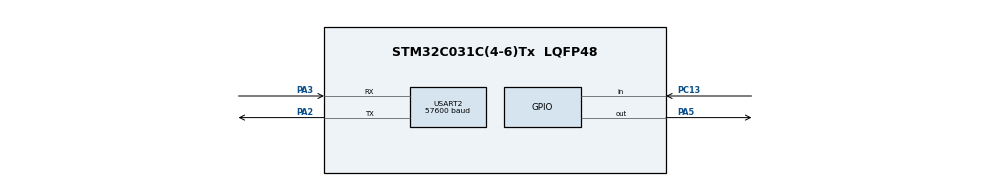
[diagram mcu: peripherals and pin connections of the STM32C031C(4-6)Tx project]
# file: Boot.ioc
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Mcu.Family=STM32C0
Mcu.Name=STM32C031C(4-6)Tx
Mcu.Package=LQFP48
PA2.Mode=Asynchronous
PA2.Signal=USART2_TX
PA3.Mode=Asynchronous
PA3.Signal=USART2_RX
PA5.Signal=GPIO_Output
PC13.Signal=GPIO_Input
PF0-OSC_IN\ (PF0).Mode=HSE-External-Oscillator
PF0-OSC_IN\ (PF0).Signal=RCC_OSC_IN
PF1-OSC_OUT\ (PF1).Mode=HSE-External-Oscillator
PF1-OSC_OUT\ (PF1).Signal=RCC_OSC_OUT
ProjectManager.HeapSize=0x200
ProjectManager.StackSize=0x400
ProjectManager.TargetToolchain=STM32CubeIDE
RCC.ADCFreq_Value=48000000
RCC.AHBFreq_Value=48000000
RCC.CortexFreq_Value=48000000
RCC.EXTERNAL_CLOCK_VALUE=12288000
RCC.HCLKFreq_Value=48000000
RCC.HSE_VALUE=48000000
RCC.HSISYSCLKDivider=RCC_HSI_DIV1
RCC.HSI_VALUE=48000000
RCC.LSE_VALUE=32768
RCC.SYSCLKFreq_VALUE=48000000
RCC.SYSCLKSource=RCC_SYSCLKSOURCE_HSE
USART2.BaudRate=57600
USART2.VirtualMode-Asynchronous=VM_ASYNC
board=NUCLEO-C031C6

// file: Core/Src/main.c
/* USER CODE BEGIN Header */
/**
  ******************************************************************************
  * @file           : main.c
  * @brief          : Main program body
  ******************************************************************************
  * @attention
  *
  * Copyright (c) 2023 STMicroelectronics.
  * All rights reserved.
  *
  * This software is licensed under terms that can be found in the LICENSE file
  * in the root directory of this software component.
  * If no LICENSE file comes with this software, it is provided AS-IS.
  *
  ******************************************************************************
  */
/* USER CODE END Header */
#include "main.h"

/* USER CODE BEGIN Includes */
#include "app.h"
/* USER CODE END Includes */

void SystemClock_Config(void);
static void MX_GPIO_Init(void);
static void MX_USART2_UART_Init(void);

int main(void)
{

  /* MCU Configuration--------------------------------------------------------*/

  /* Reset of all peripherals, Initializes the Flash interface and the Systick. */
  HAL_Init();

  /* USER CODE BEGIN Init */
  /* De-initialize the RCC to make sure the RCC_CR_HSEBYP-bit is cleared. Otherwise
   * the HSE cannot be configured, resulting in LL_RCC_HSE_IsReady() failing.
   */
  LL_RCC_DeInit();
  /* USER CODE END Init */

  /* Configure the system clock */
  SystemClock_Config();

  /* Initialize all configured peripherals */
  MX_GPIO_Init();
  MX_USART2_UART_Init();
  /* USER CODE BEGIN 2 */
  /* Initialize the bootloader application. */
  AppInit();
  /* USER CODE END 2 */

  /* Infinite loop */
  /* USER CODE BEGIN WHILE */
  while (1)
  {
    /* Run the bootloader application. */
    AppTask();
    /* USER CODE END WHILE */

  }
}

void SystemClock_Config(void)
{
  LL_FLASH_SetLatency(LL_FLASH_LATENCY_1);

  /* HSE configuration and activation */
  LL_RCC_HSE_Enable();
  while(LL_RCC_HSE_IsReady() != 1)
  {
  }

  /* Set AHB prescaler*/
  LL_RCC_SetAHBPrescaler(LL_RCC_SYSCLK_DIV_1);

  /* Sysclk activation on the HSE */
  LL_RCC_SetSysClkSource(LL_RCC_SYS_CLKSOURCE_HSE);
  while(LL_RCC_GetSysClkSource() != LL_RCC_SYS_CLKSOURCE_STATUS_HSE)
  {
  }

  /* Set APB1 prescaler*/
  LL_RCC_SetAPB1Prescaler(LL_RCC_APB1_DIV_1);
  /* Update CMSIS variable (which can be updated also through SystemCoreClockUpdate function) */
  LL_SetSystemCoreClock(48000000);

   /* Update the time base */
  if (HAL_InitTick (TICK_INT_PRIORITY) != HAL_OK)
  {
    Error_Handler();
  }
}

static void MX_USART2_UART_Init(void)
{

  LL_USART_InitTypeDef USART_InitStruct = {0};

  LL_GPIO_InitTypeDef GPIO_InitStruct = {0};

  /* Peripheral clock enable */
  LL_APB1_GRP1_EnableClock(LL_APB1_GRP1_PERIPH_USART2);

  LL_IOP_GRP1_EnableClock(LL_IOP_GRP1_PERIPH_GPIOA);
  /**USART2 GPIO Configuration
  PA2   ------> USART2_TX
  PA3   ------> USART2_RX
  */
  GPIO_InitStruct.Pin = LL_GPIO_PIN_2;
  GPIO_InitStruct.Mode = LL_GPIO_MODE_ALTERNATE;
  GPIO_InitStruct.Speed = LL_GPIO_SPEED_FREQ_LOW;
  GPIO_InitStruct.OutputType = LL_GPIO_OUTPUT_PUSHPULL;
  GPIO_InitStruct.Pull = LL_GPIO_PULL_NO;
  GPIO_InitStruct.Alternate = LL_GPIO_AF_1;
  LL_GPIO_Init(GPIOA, &GPIO_InitStruct);

  GPIO_InitStruct.Pin = LL_GPIO_PIN_3;
  GPIO_InitStruct.Mode = LL_GPIO_MODE_ALTERNATE;
  GPIO_InitStruct.Speed = LL_GPIO_SPEED_FREQ_LOW;
  GPIO_InitStruct.OutputType = LL_GPIO_OUTPUT_PUSHPULL;
  GPIO_InitStruct.Pull = LL_GPIO_PULL_NO;
  GPIO_InitStruct.Alternate = LL_GPIO_AF_1;
  LL_GPIO_Init(GPIOA, &GPIO_InitStruct);

  /* USER CODE BEGIN USART2_Init 1 */
  /* Note that the USART initialization that follows here is don't care. It is
   * reconfigured upon bootloader initialization with function Rs232Init().
   */
  /* USER CODE END USART2_Init 1 */
  USART_InitStruct.PrescalerValue = LL_USART_PRESCALER_DIV1;
  USART_InitStruct.BaudRate = 57600;
  USART_InitStruct.DataWidth = LL_USART_DATAWIDTH_8B;
  USART_InitStruct.StopBits = LL_USART_STOPBITS_1;
  USART_InitStruct.Parity = LL_USART_PARITY_NONE;
  USART_InitStruct.TransferDirection = LL_USART_DIRECTION_TX_RX;
  USART_InitStruct.HardwareFlowControl = LL_USART_HWCONTROL_NONE;
  USART_InitStruct.OverSampling = LL_USART_OVERSAMPLING_16;
  LL_USART_Init(USART2, &USART_InitStruct);
  LL_USART_ConfigAsyncMode(USART2);

  LL_USART_Enable(USART2);

  /* Polling USART2 initialisation */
  while((!(LL_USART_IsActiveFlag_TEACK(USART2))) || (!(LL_USART_IsActiveFlag_REACK(USART2))))
  {
  }

}

static void MX_GPIO_Init(void)
{
  LL_GPIO_InitTypeDef GPIO_InitStruct = {0};

  /* GPIO Ports Clock Enable */
  LL_IOP_GRP1_EnableClock(LL_IOP_GRP1_PERIPH_GPIOC);
  LL_IOP_GRP1_EnableClock(LL_IOP_GRP1_PERIPH_GPIOF);
  LL_IOP_GRP1_EnableClock(LL_IOP_GRP1_PERIPH_GPIOA);

  /**/
  LL_GPIO_ResetOutputPin(GPIOA, LL_GPIO_PIN_5);

  /**/
  GPIO_InitStruct.Pin = LL_GPIO_PIN_13;
  GPIO_InitStruct.Mode = LL_GPIO_MODE_INPUT;
  GPIO_InitStruct.Pull = LL_GPIO_PULL_NO;
  LL_GPIO_Init(GPIOC, &GPIO_InitStruct);

  /**/
  GPIO_InitStruct.Pin = LL_GPIO_PIN_5;
  GPIO_InitStruct.Mode = LL_GPIO_MODE_OUTPUT;
  GPIO_InitStruct.Speed = LL_GPIO_SPEED_FREQ_LOW;
  GPIO_InitStruct.OutputType = LL_GPIO_OUTPUT_PUSHPULL;
  GPIO_InitStruct.Pull = LL_GPIO_PULL_NO;
  LL_GPIO_Init(GPIOA, &GPIO_InitStruct);

}

void Error_Handler(void)
{
  __disable_irq();
  while (1)
  {
  }
}
